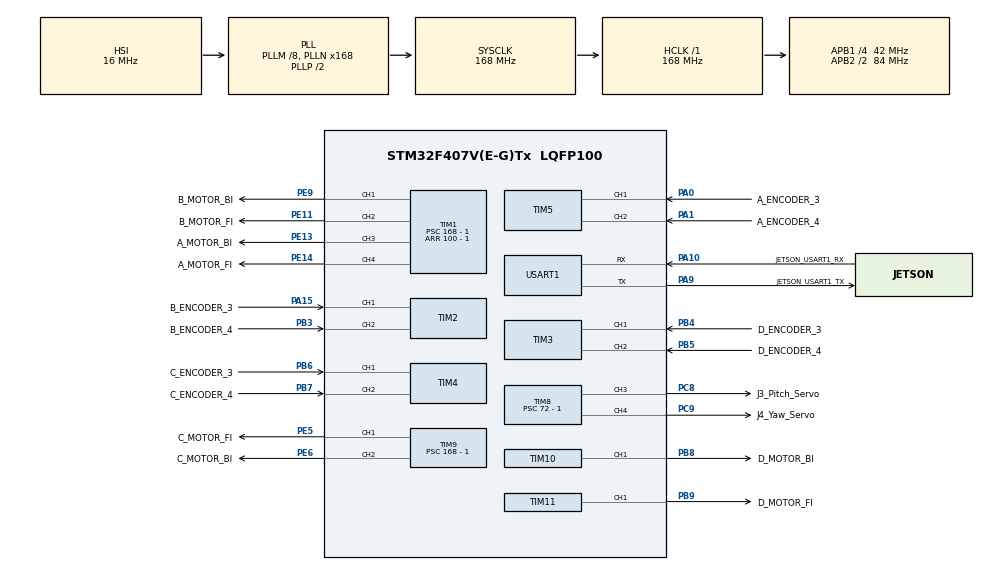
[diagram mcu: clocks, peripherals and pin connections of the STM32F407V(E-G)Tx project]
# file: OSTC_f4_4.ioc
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Dma.Request0=USART1_RX
Dma.Request1=USART1_TX
Dma.USART1_RX.0.Direction=DMA_PERIPH_TO_MEMORY
Dma.USART1_RX.0.FIFOMode=DMA_FIFOMODE_DISABLE
Dma.USART1_RX.0.Instance=DMA2_Stream2
Dma.USART1_RX.0.MemDataAlignment=DMA_MDATAALIGN_BYTE
Dma.USART1_RX.0.MemInc=DMA_MINC_ENABLE
Dma.USART1_RX.0.Mode=DMA_NORMAL
Dma.USART1_RX.0.PeriphDataAlignment=DMA_PDATAALIGN_BYTE
Dma.USART1_RX.0.PeriphInc=DMA_PINC_DISABLE
Dma.USART1_RX.0.Priority=DMA_PRIORITY_LOW
Dma.USART1_TX.1.Direction=DMA_MEMORY_TO_PERIPH
Dma.USART1_TX.1.FIFOMode=DMA_FIFOMODE_DISABLE
Dma.USART1_TX.1.Instance=DMA2_Stream7
Dma.USART1_TX.1.MemDataAlignment=DMA_MDATAALIGN_BYTE
Dma.USART1_TX.1.MemInc=DMA_MINC_ENABLE
Dma.USART1_TX.1.Mode=DMA_NORMAL
Dma.USART1_TX.1.PeriphDataAlignment=DMA_PDATAALIGN_BYTE
Dma.USART1_TX.1.PeriphInc=DMA_PINC_DISABLE
Dma.USART1_TX.1.Priority=DMA_PRIORITY_LOW
Mcu.Family=STM32F4
Mcu.Name=STM32F407V(E-G)Tx
Mcu.Package=LQFP100
NVIC.DMA2_Stream2_IRQn=true\:1\:0\:true\:false\:true\:false\:true\:true
NVIC.DMA2_Stream7_IRQn=true\:1\:0\:true\:false\:true\:false\:true\:true
NVIC.PriorityGroup=NVIC_PRIORITYGROUP_4
NVIC.TIM7_IRQn=true\:2\:0\:true\:false\:true\:true\:true\:true
NVIC.USART1_IRQn=true\:1\:0\:true\:false\:true\:true\:true\:true
PA0-WKUP.GPIO_Label=A_ENCODER_3
PA0-WKUP.Signal=S_TIM5_CH1
PA1.GPIO_Label=A_ENCODER_4
PA1.Signal=S_TIM5_CH2
PA10.GPIO_Label=JETSON_USART1_RX
PA10.Mode=Asynchronous
PA10.Signal=USART1_RX
PA13.Mode=Serial_Wire
PA13.Signal=SYS_JTMS-SWDIO
PA14.Mode=Serial_Wire
PA14.Signal=SYS_JTCK-SWCLK
PA15.GPIO_Label=B_ENCODER_3
PA15.Signal=S_TIM2_CH1_ETR
PA9.GPIO_Label=JETSON_USART1_TX
PA9.Mode=Asynchronous
PA9.Signal=USART1_TX
PB3.GPIO_Label=B_ENCODER_4
PB3.Signal=S_TIM2_CH2
PB4.GPIO_Label=D_ENCODER_3
PB4.Signal=S_TIM3_CH1
PB5.GPIO_Label=D_ENCODER_4
PB5.Signal=S_TIM3_CH2
PB6.GPIO_Label=C_ENCODER_3
PB6.Signal=S_TIM4_CH1
PB7.GPIO_Label=C_ENCODER_4
PB7.Signal=S_TIM4_CH2
PB8.GPIO_Label=D_MOTOR_BI
PB8.Signal=S_TIM10_CH1
PB9.GPIO_Label=D_MOTOR_FI
PB9.Signal=S_TIM11_CH1
PC8.GPIO_Label=J3_Pitch_Servo
PC8.Signal=S_TIM8_CH3
PC9.GPIO_Label=J4_Yaw_Servo
PC9.Signal=S_TIM8_CH4
PE11.GPIO_Label=B_MOTOR_FI
PE11.Signal=S_TIM1_CH2
PE13.GPIO_Label=A_MOTOR_BI
PE13.Signal=S_TIM1_CH3
PE14.GPIO_Label=A_MOTOR_FI
PE14.Signal=S_TIM1_CH4
PE5.GPIO_Label=C_MOTOR_FI
PE5.Signal=S_TIM9_CH1
PE6.GPIO_Label=C_MOTOR_BI
PE6.Signal=S_TIM9_CH2
PE9.GPIO_Label=B_MOTOR_BI
PE9.Signal=S_TIM1_CH1
PH0-OSC_IN.Mode=HSE-External-Oscillator
PH0-OSC_IN.Signal=RCC_OSC_IN
PH1-OSC_OUT.Mode=HSE-External-Oscillator
PH1-OSC_OUT.Signal=RCC_OSC_OUT
ProjectManager.HeapSize=0x200
ProjectManager.StackSize=0x400
ProjectManager.TargetToolchain=STM32CubeIDE
RCC.48MHZClocksFreq_Value=84000000
RCC.AHBFreq_Value=168000000
RCC.APB1CLKDivider=RCC_HCLK_DIV4
RCC.APB1Freq_Value=42000000
RCC.APB1TimFreq_Value=84000000
RCC.APB2CLKDivider=RCC_HCLK_DIV2
RCC.APB2Freq_Value=84000000
RCC.APB2TimFreq_Value=168000000
RCC.CortexFreq_Value=168000000
RCC.HCLKFreq_Value=168000000
RCC.HSE_VALUE=8000000
RCC.HSI_VALUE=16000000
RCC.LSE_VALUE=32768
RCC.PLLM=8
RCC.PLLN=168
RCC.SYSCLKFreq_VALUE=168000000
RCC.SYSCLKSource=RCC_SYSCLKSOURCE_PLLCLK
RCC.VCOOutputFreq_Value=336000000
SH.S_TIM10_CH1.0=TIM10_CH1,PWM Generation1 CH1
SH.S_TIM11_CH1.0=TIM11_CH1,PWM Generation1 CH1
SH.S_TIM1_CH1.0=TIM1_CH1,PWM Generation1 CH1
SH.S_TIM1_CH2.0=TIM1_CH2,PWM Generation2 CH2
SH.S_TIM1_CH3.0=TIM1_CH3,PWM Generation3 CH3
SH.S_TIM1_CH4.0=TIM1_CH4,PWM Generation4 CH4
SH.S_TIM2_CH1_ETR.0=TIM2_CH1,Encoder_Interface
SH.S_TIM2_CH2.0=TIM2_CH2,Encoder_Interface
SH.S_TIM3_CH1.0=TIM3_CH1,Encoder_Interface
SH.S_TIM3_CH2.0=TIM3_CH2,Encoder_Interface
SH.S_TIM4_CH1.0=TIM4_CH1,Encoder_Interface
SH.S_TIM4_CH2.0=TIM4_CH2,Encoder_Interface
SH.S_TIM5_CH1.0=TIM5_CH1,Encoder_Interface
SH.S_TIM5_CH2.0=TIM5_CH2,Encoder_Interface
SH.S_TIM8_CH3.0=TIM8_CH3,PWM Generation3 CH3
SH.S_TIM8_CH4.0=TIM8_CH4,PWM Generation4 CH4
SH.S_TIM9_CH1.0=TIM9_CH1,PWM Generation1 CH1
SH.S_TIM9_CH2.0=TIM9_CH2,PWM Generation2 CH2
TIM1.Channel-PWM\ Generation1\ CH1=TIM_CHANNEL_1
TIM1.Channel-PWM\ Generation2\ CH2=TIM_CHANNEL_2
TIM1.Channel-PWM\ Generation3\ CH3=TIM_CHANNEL_3
TIM1.Channel-PWM\ Generation4\ CH4=TIM_CHANNEL_4
TIM1.Period=100 - 1
TIM1.Prescaler=168 - 1
TIM1.Pulse-PWM\ Generation1\ CH1=0
TIM1.Pulse-PWM\ Generation2\ CH2=0
TIM1.Pulse-PWM\ Generation3\ CH3=0
TIM1.Pulse-PWM\ Generation4\ CH4=0
TIM10.Channel=TIM_CHANNEL_1
TIM10.Period=100 - 1
TIM10.Prescaler=168 - 1
TIM10.Pulse=0
TIM11.Channel=TIM_CHANNEL_1
TIM11.Period=100 - 1
TIM11.Prescaler=168 - 1
TIM11.Pulse=0
TIM2.EncoderMode=TIM_ENCODERMODE_TI12
TIM3.EncoderMode=TIM_ENCODERMODE_TI12
TIM4.EncoderMode=TIM_ENCODERMODE_TI12
TIM5.EncoderMode=TIM_ENCODERMODE_TI12
TIM7.Period=100 - 1
TIM7.Prescaler=8400 - 1
TIM8.Channel-PWM\ Generation3\ CH3=TIM_CHANNEL_3
TIM8.Channel-PWM\ Generation4\ CH4=TIM_CHANNEL_4
TIM8.Period=20000 - 1
TIM8.Prescaler=72 - 1
TIM9.Channel-PWM\ Generation1\ CH1=TIM_CHANNEL_1
TIM9.Channel-PWM\ Generation2\ CH2=TIM_CHANNEL_2
TIM9.Period=100 - 1
TIM9.Prescaler=168 - 1
TIM9.Pulse-PWM\ Generation1\ CH1=0
TIM9.Pulse-PWM\ Generation2\ CH2=0
USART1.VirtualMode=VM_ASYNC
VP_TIM10_VS_ClockSourceINT.Mode=Enable_Timer
VP_TIM11_VS_ClockSourceINT.Mode=Enable_Timer
VP_TIM1_VS_ClockSourceINT.Mode=Internal
VP_TIM7_VS_ClockSourceINT.Mode=Enable_Timer
VP_TIM8_VS_ClockSourceINT.Mode=Internal
VP_TIM9_VS_ClockSourceINT.Mode=Internal
board=custom

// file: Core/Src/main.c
/* USER CODE BEGIN Header */
/**
  ******************************************************************************
  * @file           : main.c
  * @brief          : Main program body
  ******************************************************************************
  * @attention
  *
  * Copyright (c) 2025 STMicroelectronics.
  * All rights reserved.
  *
  * This software is licensed under terms that can be found in the LICENSE file
  * in the root directory of this software component.
  * If no LICENSE file comes with this software, it is provided AS-IS.
  *
  ******************************************************************************
  */
/* USER CODE END Header */
#include "main.h"
#include "dma.h"
#include "tim.h"
#include "usart.h"
#include "gpio.h"

/* USER CODE BEGIN Includes */
#include <string.h>

#include "Setup_and_Loop.h"
#include "robot.h"
#include "servo.h"
#include "jetson.h"
/* USER CODE END Includes */

void SystemClock_Config(void);

int main(void)
{

  /* MCU Configuration--------------------------------------------------------*/

  /* Reset of all peripherals, Initializes the Flash interface and the Systick. */
  HAL_Init();

  /* Configure the system clock */
  SystemClock_Config();

  /* Initialize all configured peripherals */
  MX_GPIO_Init();
  MX_DMA_Init();
  MX_TIM1_Init();
  MX_TIM2_Init();
  MX_TIM3_Init();
  MX_TIM4_Init();
  MX_TIM5_Init();
  MX_TIM9_Init();
  MX_TIM10_Init();
  MX_TIM11_Init();
  MX_TIM8_Init();
  MX_USART1_UART_Init();
  MX_TIM7_Init();

  /* Infinite loop */
  /* USER CODE BEGIN WHILE */

  setup(robot_init());

  while (1)
  {

    // HAL_UART_Transmit(&huart1, (uint8_t*)message, strlen(message), 100);
    // HAL_Delay(1000);
    // HAL_UART_Receive(&huart1, receiveData, 2, HAL_MAX_DELAY);

    // HAL_UART_Transmit(&huart1, receiveData,2,100);

    loop(robot_init());
    /* USER CODE END WHILE */

  }
}

void SystemClock_Config(void)
{
  RCC_OscInitTypeDef RCC_OscInitStruct = {0};
  RCC_ClkInitTypeDef RCC_ClkInitStruct = {0};

  /** Configure the main internal regulator output voltage
  */
  __HAL_RCC_PWR_CLK_ENABLE();
  __HAL_PWR_VOLTAGESCALING_CONFIG(PWR_REGULATOR_VOLTAGE_SCALE1);

  /** Initializes the RCC Oscillators according to the specified parameters
  * in the RCC_OscInitTypeDef structure.
  */
  RCC_OscInitStruct.OscillatorType = RCC_OSCILLATORTYPE_HSI;
  RCC_OscInitStruct.HSIState = RCC_HSI_ON;
  RCC_OscInitStruct.HSICalibrationValue = RCC_HSICALIBRATION_DEFAULT;
  RCC_OscInitStruct.PLL.PLLState = RCC_PLL_ON;
  RCC_OscInitStruct.PLL.PLLSource = RCC_PLLSOURCE_HSI;
  RCC_OscInitStruct.PLL.PLLM = 8;
  RCC_OscInitStruct.PLL.PLLN = 168;
  RCC_OscInitStruct.PLL.PLLP = RCC_PLLP_DIV2;
  RCC_OscInitStruct.PLL.PLLQ = 4;
  if (HAL_RCC_OscConfig(&RCC_OscInitStruct) != HAL_OK)
  {
    Error_Handler();
  }

  /** Initializes the CPU, AHB and APB buses clocks
  */
  RCC_ClkInitStruct.ClockType = RCC_CLOCKTYPE_HCLK|RCC_CLOCKTYPE_SYSCLK
                              |RCC_CLOCKTYPE_PCLK1|RCC_CLOCKTYPE_PCLK2;
  RCC_ClkInitStruct.SYSCLKSource = RCC_SYSCLKSOURCE_PLLCLK;
  RCC_ClkInitStruct.AHBCLKDivider = RCC_SYSCLK_DIV1;
  RCC_ClkInitStruct.APB1CLKDivider = RCC_HCLK_DIV4;
  RCC_ClkInitStruct.APB2CLKDivider = RCC_HCLK_DIV2;

  if (HAL_RCC_ClockConfig(&RCC_ClkInitStruct, FLASH_LATENCY_5) != HAL_OK)
  {
    Error_Handler();
  }
}

void Error_Handler(void)
{
  __disable_irq();
  while (1)
  {
  }
}
